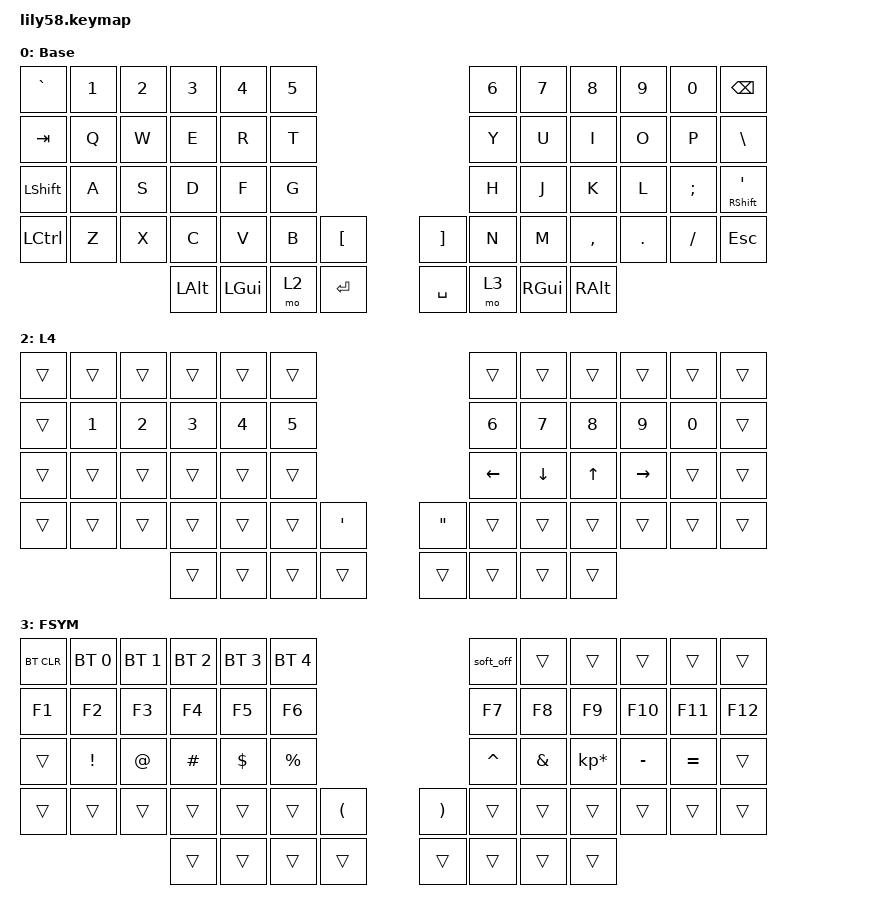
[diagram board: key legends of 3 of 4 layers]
/*
 * Copyright (c) 2020 The ZMK Contributors
 *
 * SPDX-License-Identifier: MIT
 */

#include <behaviors.dtsi>
#include <dt-bindings/zmk/bt.h>
#include <dt-bindings/zmk/keys.h>

/ {
    keymap {
        compatible = "zmk,keymap";

        QWERTY {
            // ------------------------------------------------------------------------------------------------------------
            // |  ESC  |  1  |  2  |  3   |  4   |  5   |                   |  6   |  7    |  8    |  9   |   0   |   `   |
            // |  TAB  |  Q  |  W  |  E   |  R   |  T   |                   |  Y   |  U    |  I    |  O   |   P   |   -   |
            // |  CTRL |  A  |  S  |  D   |  F   |  G   |                   |  H   |  J    |  K    |  L   |   ;   |   '   |
            // | SHIFT |  Z  |  X  |  C   |  V   |  B   |   "["  |  |  "]"  |  N   |  M    |  ,    |  .   |   /   | SHIFT |
            //                     | ALT  | GUI  | LOWER|  SPACE |  | ENTER | RAISE| BSPC  | GUI   |

            display-name = "Base";
            bindings = <
&kp GRAVE         &kp N1  &kp N2  &kp N3    &kp N4    &kp N5                                         &kp N6  &kp N7         &kp N8         &kp N9   &kp N0    &kp BACKSPACE
&kp TAB           &kp Q   &kp W   &kp E     &kp R     &kp T                                          &kp Y   &kp U          &kp I          &kp O    &kp P     &kp BACKSLASH
&kp LEFT_SHIFT    &kp A   &kp S   &kp D     &kp F     &kp G                                          &kp H   &kp J          &kp K          &kp L    &kp SEMI  &mt RIGHT_SHIFT SQT
&kp LEFT_CONTROL  &kp Z   &kp X   &kp C     &kp V     &kp B   &kp LEFT_BRACKET    &kp RIGHT_BRACKET  &kp N   &kp M          &kp COMMA      &kp DOT  &kp FSLH  &kp ESCAPE
                                  &kp LALT  &kp LGUI  &mo 2   &kp ENTER           &kp SPACE          &mo 3   &kp RIGHT_GUI  &kp RIGHT_ALT
            >;
        };

        COLE {
            // ------------------------------------------------------------------------------------------------------------
            // |  ESC  |  1  |  2  |  3   |  4   |  5   |                   |  6   |  7    |  8    |  9   |   0   |   `   |
            // |  TAB  |  Q  |  W  |  E   |  R   |  T   |                   |  Y   |  U    |  I    |  O   |   P   |   -   |
            // |  CTRL |  A  |  S  |  D   |  F   |  G   |                   |  H   |  J    |  K    |  L   |   ;   |   '   |
            // | SHIFT |  Z  |  X  |  C   |  V   |  B   |   "["  |  |  "]"  |  N   |  M    |  ,    |  .   |   /   | SHIFT |
            //                     | ALT  | GUI  | LOWER|  SPACE |  | ENTER | RAISE| BSPC  | GUI   |

            display-name = "COLE";
            bindings = <
&trans  &trans  &trans  &trans  &trans  &trans                    &trans  &trans  &trans  &trans  &trans  &trans
&trans  &kp Q   &kp W   &kp F   &kp P   &kp B                     &kp J   &kp L   &kp U   &kp Y   &trans  &trans
&trans  &kp A   &kp R   &kp S   &kp T   &kp D                     &kp H   &kp N   &kp E   &kp I   &kp O   &trans
&trans  &kp Z   &kp X   &kp C   &kp V   &kp B   &trans    &trans  &kp K   &kp M   &trans  &trans  &trans  &trans
                        &trans  &trans  &trans  &trans    &trans  &trans
            >;
        };

        ARNUM {
            label = "ARNUM";
            display-name = "L4";
            bindings = <
&trans  &trans  &trans  &trans  &trans  &trans                                         &trans          &trans    &trans        &trans     &trans  &trans
&trans  &kp N1  &kp N2  &kp N3  &kp N4  &kp N5                                         &kp N6          &kp N7    &kp N8        &kp N9     &kp N0  &trans
&trans  &trans  &trans  &trans  &trans  &trans                                         &kp LEFT_ARROW  &kp DOWN  &kp UP_ARROW  &kp RIGHT  &trans  &trans
&trans  &trans  &trans  &trans  &trans  &trans  &kp SINGLE_QUOTE    &kp DOUBLE_QUOTES  &trans          &trans    &trans        &trans     &trans  &trans
                        &trans  &trans  &trans  &trans              &trans             &trans          &trans    &trans
            >;
        };

        FSYM {
            label = "FSYM";
            display-name = "FSYM";
            bindings = <
&bt BT_CLR  &bt BT_SEL 0  &bt BT_SEL 1  &bt BT_SEL 2  &bt BT_SEL 3  &bt BT_SEL 4                                                 &soft_off  &trans    &trans           &trans     &trans     &trans
&kp F1      &kp F2        &kp F3        &kp F4        &kp F5        &kp F6                                                       &kp F7     &kp F8    &kp F9           &kp F10    &kp F11    &kp F12
&trans      &kp EXCL      &kp AT        &kp HASH      &kp DOLLAR    &kp PRCNT                                                    &kp CARET  &kp AMPS  &kp KP_MULTIPLY  &kp MINUS  &kp EQUAL  &trans
&trans      &trans        &trans        &trans        &trans        &trans        &kp LEFT_PARENTHESIS    &kp RIGHT_PARENTHESIS  &trans     &trans    &trans           &trans     &trans     &trans
                                        &trans        &trans        &trans        &trans                  &trans                 &trans     &trans    &trans
            >;
        };
    };
};
